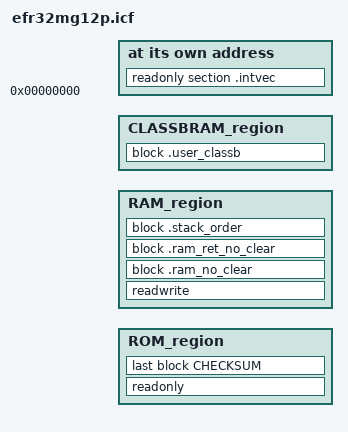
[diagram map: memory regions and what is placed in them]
/*###ICF### Section handled by ICF editor, don't touch! ****/
/*-Editor annotation file-*/
/* IcfEditorFile="$TOOLKIT_DIR$\config\ide\IcfEditor\cortex_v1_0.xml" */

/*-Specials-*/
define symbol __ICFEDIT_intvec_start__ = 0x00000000;

/*-Memory Regions-*/
define symbol __ICFEDIT_region_ROM_start__   = 0x00000000;
define symbol __ICFEDIT_region_ROM_end__     = (0x00000000+0x00100000-1);
define symbol __ICFEDIT_region_RAM_start__   = 0x20000080;
define symbol __ICFEDIT_region_RAM_end__     = (0x20000000+0x00040000-1);
define symbol __ICFEDIT_region_CLASSBRAM_start__   = 0x20000000;
define symbol __ICFEDIT_region_CLASSBRAM_end__     = (0x20000000+0x00000080-1);

/*-Sizes-*/
if ( !isdefinedsymbol( __ICFEDIT_size_cstack__ ) )
{ define symbol __ICFEDIT_size_cstack__   = 0x400; }

if ( !isdefinedsymbol( __ICFEDIT_size_heap__ ) )
{ define symbol __ICFEDIT_size_heap__     = 0x800; }

define exported symbol __FlashStart = __ICFEDIT_region_ROM_start__;
define exported symbol __StackTop = __ICFEDIT_region_RAM_end__;
define exported symbol __RamStart = __ICFEDIT_region_CLASSBRAM_start__;
define exported symbol __ClassBLimit = __ICFEDIT_region_CLASSBRAM_end__ + 1;

/**** End of ICF editor section. ###ICF###*/

define memory mem with size = 4G;
define region ROM_region   = mem:[from __ICFEDIT_region_ROM_start__   to __ICFEDIT_region_ROM_end__];
define region RAM_region   = mem:[from __ICFEDIT_region_RAM_start__   to __ICFEDIT_region_RAM_end__];
define region CLASSBRAM_region   = mem:[from __ICFEDIT_region_CLASSBRAM_start__   to __ICFEDIT_region_CLASSBRAM_end__];

define block CSTACK    with alignment = 8, size = __ICFEDIT_size_cstack__   { };
define block HEAP      with alignment = 8, size = __ICFEDIT_size_heap__     { };

define block CHECKSUM  with alignment = 64 { section .checksum };

define root section classb_start { public __classb_start: };
define root section classb_end { public __classb_end: };

define block .user_classb with fixed order, alignment = 4,
                                size = (__ICFEDIT_region_CLASSBRAM_end__ - __ICFEDIT_region_CLASSBRAM_start__ + 1)
                            { section *.rt_buf,
                              section *.rt_buf*,
                              section *.overlap*,
                              section classb_start,
                              section *.classb_ram,
                              section *.classb_ram*,
                              section classb_end
                            };

keep { section *.overlap* };

define block .ram_no_clear     with alignment = 4 { section *.ram_no_clear* };
define block .ram_ret_no_clear with alignment = 4 { section *.ram_ret_no_clear* };
define block .ram_check        with alignment = 8 { section *.stack_bottom* };
define block .stack_order with fixed order { block .ram_check, block CSTACK, block HEAP };

do not initialize { section *.ram_no_clear* };
do not initialize { section *.ram_ret_no_clear* };

initialize by copy { readwrite };

keep { section .intvec };
place at address mem:__ICFEDIT_intvec_start__ { readonly section .intvec };

place in ROM_region   { readonly, last block CHECKSUM };
place in RAM_region   { readwrite,
                        block .ram_no_clear,
                        block .ram_ret_no_clear,
                        block .stack_order };

"CLASSB_RAM": place noload in CLASSBRAM_region   { block .user_classb };
